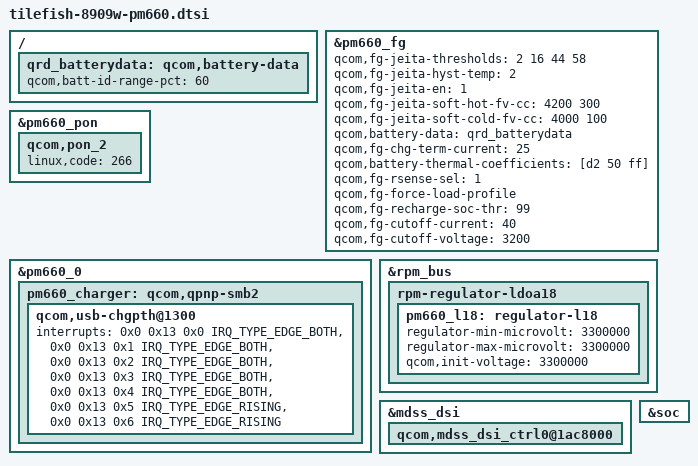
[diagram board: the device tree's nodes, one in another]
/*
 * Copyright (c) 2017-2018, The Linux Foundation. All rights reserved.
 *
 * This program is free software; you can redistribute it and/or modify
 * it under the terms of the GNU General Public License version 2 and
 * only version 2 as published by the Free Software Foundation.
 *
 * This program is distributed in the hope that it will be useful,
 * but WITHOUT ANY WARRANTY; without even the implied warranty of
 * MERCHANTABILITY or FITNESS FOR A PARTICULAR PURPOSE.  See the
 * GNU General Public License for more details.
 */
#include "incell-touch.dtsi"

&pm660_fg {
	qcom,fg-jeita-thresholds = <2 16 44 58>;
	qcom,fg-jeita-hyst-temp = <2>;
	qcom,fg-jeita-en = <1>;
	qcom,fg-jeita-soft-hot-fv-cc = <4200 300>;
	qcom,fg-jeita-soft-cold-fv-cc = <4000 100>;
	qcom,battery-data = <&qrd_batterydata>;
	qcom,fg-chg-term-current = <25>;
	qcom,battery-thermal-coefficients = [d2 50 ff];
	qcom,fg-rsense-sel = <1>;
	qcom,fg-force-load-profile;
	qcom,fg-recharge-soc-thr = <99>;
	qcom,fg-cutoff-current = <40>;
	qcom,fg-cutoff-voltage = <3200>;
};

/ {
	/delete-node/ qcom,battery-data;
	qrd_batterydata: qcom,battery-data {
		qcom,batt-id-range-pct = <60>;
		#include "tilefish-fg-gen3-batterydata-apack-300mah.dtsi"
	};
};

&pm660_pon {
	qcom,pon_2 {
		linux,code = <266>;
	};
};

&pm660_0 {
	pm660_charger: qcom,qpnp-smb2 {
		qcom,usb-chgpth@1300 {
			interrupts =
				<0x0 0x13 0x0 IRQ_TYPE_EDGE_BOTH>,
				<0x0 0x13 0x1 IRQ_TYPE_EDGE_BOTH>,
				<0x0 0x13 0x2 IRQ_TYPE_EDGE_BOTH>,
				<0x0 0x13 0x3 IRQ_TYPE_EDGE_BOTH>,
				<0x0 0x13 0x4 IRQ_TYPE_EDGE_BOTH>,
				<0x0 0x13 0x5 IRQ_TYPE_EDGE_RISING>,
				<0x0 0x13 0x6 IRQ_TYPE_EDGE_RISING>;

			interrupt-names = "usbin-collapse",
				"usbin-lt-3p6v",
				"usbin-uv",
				"usbin-ov",
				"usbin-plugin",
				"usbin-src-change",
				"usbin-icl-change";
		};
	};
};

&rpm_bus {
	rpm-regulator-ldoa18 {
		pm660_l18: regulator-l18 {
			/delete-property/ supply-min-voltage;
			/delete-property/ supply-max-voltage;
			/delete-property/ qcom,init-voltage;
			regulator-min-microvolt = <3300000>;
			regulator-max-microvolt = <3300000>;
			qcom,init-voltage = <3300000>;
		};
	};
};

&mdss_dsi {
	qcom,mdss_dsi_ctrl0@1ac8000 {
		/delete-property/ bklt-supply;
	};
};

&soc {
	/delete-node/ bob_vreg;
};
